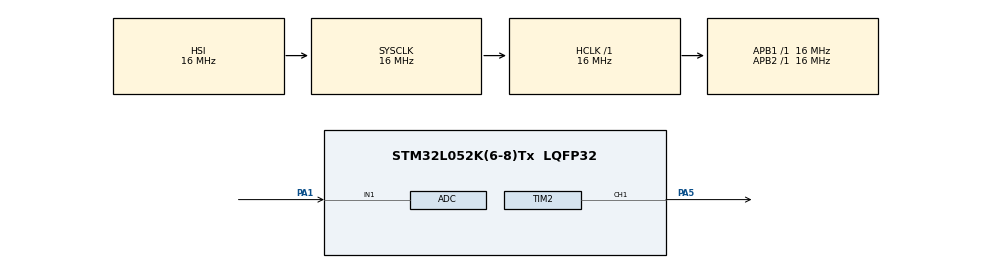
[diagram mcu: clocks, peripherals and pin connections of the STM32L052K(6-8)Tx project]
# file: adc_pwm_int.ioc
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ADC.ContinuousConvMode=ENABLE
Mcu.Family=STM32L0
Mcu.Name=STM32L052K(6-8)Tx
Mcu.Package=LQFP32
NVIC.ADC1_COMP_IRQn=true\:0\:0\:false\:false\:true\:true\:true\:true
NVIC.TIM2_IRQn=true\:0\:0\:false\:false\:true\:true\:true\:true
PA1.Mode=IN1
PA1.Signal=ADC_IN1
PA13.Mode=Serial_Wire
PA13.Signal=SYS_SWDIO
PA14.Mode=Serial_Wire
PA14.Signal=SYS_SWCLK
PA5.GPIO_PuPd=GPIO_NOPULL
PA5.Signal=S_TIM2_CH1
ProjectManager.HeapSize=0x200
ProjectManager.StackSize=0x400
ProjectManager.TargetToolchain=STM32CubeIDE
RCC.AHBFreq_Value=16000000
RCC.APB1Freq_Value=16000000
RCC.APB1TimFreq_Value=16000000
RCC.APB2Freq_Value=16000000
RCC.APB2TimFreq_Value=16000000
RCC.HCLKFreq_Value=16000000
RCC.HSI16_VALUE=16000000
RCC.HSI48_VALUE=48000000
RCC.HSI_VALUE=16000000
RCC.LSE_VALUE=32768
RCC.MSI_VALUE=2097000
RCC.SYSCLKFreq_VALUE=16000000
RCC.SYSCLKSource=RCC_SYSCLKSOURCE_HSI
RCC.VCOOutputFreq_Value=48000000
SH.S_TIM2_CH1.0=TIM2_CH1,PWM Generation1 CH1
TIM2.AutoReloadPreload=TIM_AUTORELOAD_PRELOAD_ENABLE
TIM2.Channel-PWM\ Generation1\ CH1=TIM_CHANNEL_1
VP_TIM2_VS_ClockSourceINT.Mode=Internal
board=custom

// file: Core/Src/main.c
/* USER CODE BEGIN Header */
/**
  ******************************************************************************
  * @file           : main.c
  * @brief          : Main program body
  ******************************************************************************
  * @attention
  *
  * Copyright (c) 2022 STMicroelectronics.
  * All rights reserved.
  *
  * This software is licensed under terms that can be found in the LICENSE file
  * in the root directory of this software component.
  * If no LICENSE file comes with this software, it is provided AS-IS.
  *
  ******************************************************************************
  */
/* USER CODE END Header */
#include "main.h"

ADC_HandleTypeDef hadc;

TIM_HandleTypeDef htim2;

/* USER CODE BEGIN PV */
	uint8_t scan = 0;
	uint16_t vr_val = 0, VAL=0;
/* USER CODE END PV */

void SystemClock_Config(void);
static void MX_GPIO_Init(void);
static void MX_ADC_Init(void);
static void MX_TIM2_Init(void);

/* USER CODE BEGIN 0 */
void HAL_IncTick(void)
{
 uwTick += uwTickFreq;
 if(uwTick % 200 == 0){
		scan = SET;
 }
}
void HAL_ADC_ConvCpltCallback(ADC_HandleTypeDef* hadc)
{
	if(__HAL_ADC_GET_FLAG(hadc, ADC_FLAG_EOC)){
			vr_val = HAL_ADC_GetValue(hadc);
			VAL = vr_val<<4;
	}
}
void HAL_TIM_PeriodElapsedCallback(TIM_HandleTypeDef *htim)
{
	TIM2->CCR1 = VAL;
}
/* USER CODE END 0 */

int main(void)
{

  /* MCU Configuration--------------------------------------------------------*/

  /* Reset of all peripherals, Initializes the Flash interface and the Systick. */
  HAL_Init();

  /* Configure the system clock */
  SystemClock_Config();

  /* Initialize all configured peripherals */
  MX_GPIO_Init();
  MX_ADC_Init();
  MX_TIM2_Init();
  /* USER CODE BEGIN 2 */
  HAL_ADC_Start_IT(&hadc);
  HAL_TIM_PWM_Start_IT(&htim2, TIM_CHANNEL_1);
  /* USER CODE END 2 */

  /* Infinite loop */
  while (1)
  {

    /* USER CODE BEGIN 3 */
  		if(scan == SET){
  				scan = RESET;
  				HAL_ADC_Start_IT(&hadc);
  		}
  		__NOP();
  }
  /* USER CODE END 3 */
}

void SystemClock_Config(void)
{
  RCC_OscInitTypeDef RCC_OscInitStruct = {0};
  RCC_ClkInitTypeDef RCC_ClkInitStruct = {0};

  /** Configure the main internal regulator output voltage
  */
  __HAL_PWR_VOLTAGESCALING_CONFIG(PWR_REGULATOR_VOLTAGE_SCALE1);

  /** Initializes the RCC Oscillators according to the specified parameters
  * in the RCC_OscInitTypeDef structure.
  */
  RCC_OscInitStruct.OscillatorType = RCC_OSCILLATORTYPE_HSI;
  RCC_OscInitStruct.HSIState = RCC_HSI_ON;
  RCC_OscInitStruct.HSICalibrationValue = RCC_HSICALIBRATION_DEFAULT;
  RCC_OscInitStruct.PLL.PLLState = RCC_PLL_NONE;
  if (HAL_RCC_OscConfig(&RCC_OscInitStruct) != HAL_OK)
  {
    Error_Handler();
  }

  /** Initializes the CPU, AHB and APB buses clocks
  */
  RCC_ClkInitStruct.ClockType = RCC_CLOCKTYPE_HCLK|RCC_CLOCKTYPE_SYSCLK
                              |RCC_CLOCKTYPE_PCLK1|RCC_CLOCKTYPE_PCLK2;
  RCC_ClkInitStruct.SYSCLKSource = RCC_SYSCLKSOURCE_HSI;
  RCC_ClkInitStruct.AHBCLKDivider = RCC_SYSCLK_DIV1;
  RCC_ClkInitStruct.APB1CLKDivider = RCC_HCLK_DIV1;
  RCC_ClkInitStruct.APB2CLKDivider = RCC_HCLK_DIV1;

  if (HAL_RCC_ClockConfig(&RCC_ClkInitStruct, FLASH_LATENCY_0) != HAL_OK)
  {
    Error_Handler();
  }
}

static void MX_ADC_Init(void)
{

  ADC_ChannelConfTypeDef sConfig = {0};

  /** Configure the global features of the ADC (Clock, Resolution, Data Alignment and number of conversion)
  */
  hadc.Instance = ADC1;
  hadc.Init.OversamplingMode = DISABLE;
  hadc.Init.ClockPrescaler = ADC_CLOCK_SYNC_PCLK_DIV1;
  hadc.Init.Resolution = ADC_RESOLUTION_12B;
  hadc.Init.SamplingTime = ADC_SAMPLETIME_1CYCLE_5;
  hadc.Init.ScanConvMode = ADC_SCAN_DIRECTION_FORWARD;
  hadc.Init.DataAlign = ADC_DATAALIGN_RIGHT;
  hadc.Init.ContinuousConvMode = ENABLE;
  hadc.Init.DiscontinuousConvMode = DISABLE;
  hadc.Init.ExternalTrigConvEdge = ADC_EXTERNALTRIGCONVEDGE_NONE;
  hadc.Init.ExternalTrigConv = ADC_SOFTWARE_START;
  hadc.Init.DMAContinuousRequests = DISABLE;
  hadc.Init.EOCSelection = ADC_EOC_SINGLE_CONV;
  hadc.Init.Overrun = ADC_OVR_DATA_PRESERVED;
  hadc.Init.LowPowerAutoWait = DISABLE;
  hadc.Init.LowPowerFrequencyMode = DISABLE;
  hadc.Init.LowPowerAutoPowerOff = DISABLE;
  if (HAL_ADC_Init(&hadc) != HAL_OK)
  {
    Error_Handler();
  }

  /** Configure for the selected ADC regular channel to be converted.
  */
  sConfig.Channel = ADC_CHANNEL_1;
  sConfig.Rank = ADC_RANK_CHANNEL_NUMBER;
  if (HAL_ADC_ConfigChannel(&hadc, &sConfig) != HAL_OK)
  {
    Error_Handler();
  }

}

static void MX_TIM2_Init(void)
{

  TIM_ClockConfigTypeDef sClockSourceConfig = {0};
  TIM_MasterConfigTypeDef sMasterConfig = {0};
  TIM_OC_InitTypeDef sConfigOC = {0};

  htim2.Instance = TIM2;
  htim2.Init.Prescaler = 0;
  htim2.Init.CounterMode = TIM_COUNTERMODE_UP;
  htim2.Init.Period = 65535;
  htim2.Init.ClockDivision = TIM_CLOCKDIVISION_DIV1;
  htim2.Init.AutoReloadPreload = TIM_AUTORELOAD_PRELOAD_ENABLE;
  if (HAL_TIM_Base_Init(&htim2) != HAL_OK)
  {
    Error_Handler();
  }
  sClockSourceConfig.ClockSource = TIM_CLOCKSOURCE_INTERNAL;
  if (HAL_TIM_ConfigClockSource(&htim2, &sClockSourceConfig) != HAL_OK)
  {
    Error_Handler();
  }
  if (HAL_TIM_PWM_Init(&htim2) != HAL_OK)
  {
    Error_Handler();
  }
  sMasterConfig.MasterOutputTrigger = TIM_TRGO_RESET;
  sMasterConfig.MasterSlaveMode = TIM_MASTERSLAVEMODE_DISABLE;
  if (HAL_TIMEx_MasterConfigSynchronization(&htim2, &sMasterConfig) != HAL_OK)
  {
    Error_Handler();
  }
  sConfigOC.OCMode = TIM_OCMODE_PWM1;
  sConfigOC.Pulse = 0;
  sConfigOC.OCPolarity = TIM_OCPOLARITY_HIGH;
  sConfigOC.OCFastMode = TIM_OCFAST_DISABLE;
  if (HAL_TIM_PWM_ConfigChannel(&htim2, &sConfigOC, TIM_CHANNEL_1) != HAL_OK)
  {
    Error_Handler();
  }
  HAL_TIM_MspPostInit(&htim2);

}

static void MX_GPIO_Init(void)
{

  /* GPIO Ports Clock Enable */
  __HAL_RCC_GPIOA_CLK_ENABLE();

}

void Error_Handler(void)
{
  __disable_irq();
  while (1)
  {
  }
}
